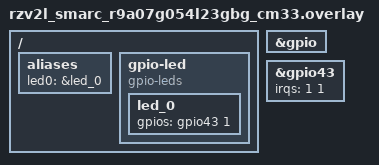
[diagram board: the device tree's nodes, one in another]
/*
 * Copyright (c) 2025 Renesas Electronics Corporation
 * SPDX-License-Identifier: Apache-2.0
 */

/ {
	aliases {
		led0 = &led_0;
	};

	gpio-led {
		compatible = "gpio-leds";
		led_0: led_0 {
			gpios = <&gpio43 1 0>;
		};
	};
};

&gpio {
	status = "okay";
};

&gpio43 {
	irqs = <1 1>;
	status = "okay";
};
